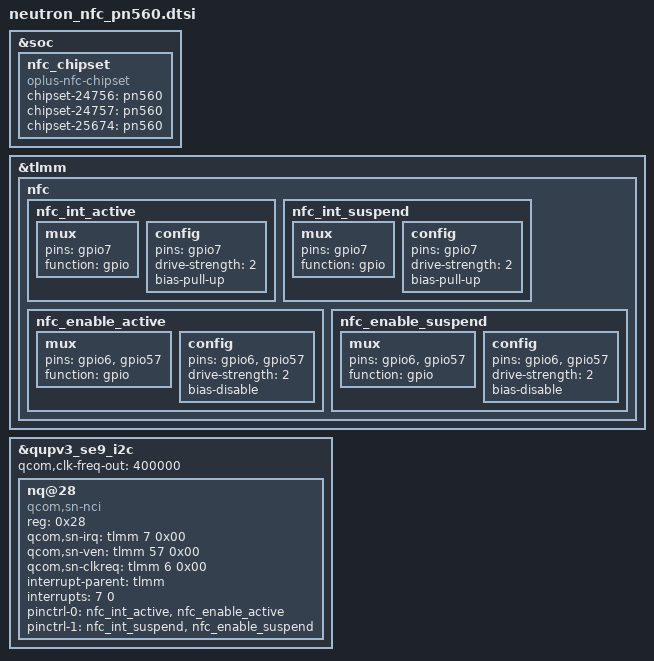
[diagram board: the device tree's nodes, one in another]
&soc {
    //add for nfc_chipset
    nfc_chipset {
        compatible = "oplus-nfc-chipset";
        chipset-24756 = "pn560";
        chipset-24757 = "pn560";
        chipset-25674 = "pn560";
    };
};


&tlmm {
	nfc {
		nfc_int_active: nfc_int_active {
			/* active state */
			mux {
				/* GPIO 7 NFC Read Interrupt */
				pins = "gpio7";
				function = "gpio";
			};

			config {
				pins = "gpio7";
				drive-strength = <2>; /* 2 MA */
				bias-pull-up;
			};
		};

		nfc_int_suspend: nfc_int_suspend {
			/* sleep state */
			mux {
				/* GPIO 7 NFC Read Interrupt */
				pins = "gpio7";
				function = "gpio";
			};

			config {
				pins = "gpio7";
				drive-strength = <2>; /* 2 MA */
				bias-pull-up;
			};
		};

		nfc_enable_active: nfc_enable_active {
            mux {
                /* Enable, Clock request gpios */
                pins = "gpio6", "gpio57";
                function = "gpio";
            };

            config {
                pins = "gpio6", "gpio57";
                drive-strength = <2>; /* 2 MA */
                bias-disable;
            };
        };

        nfc_enable_suspend: nfc_enable_suspend {
            mux {
                pins = "gpio6", "gpio57";
                function = "gpio";
            };

            config {
                pins = "gpio6", "gpio57";
                drive-strength = <2>; /* 2 MA */
                bias-disable;
			};
		};
	};
};

&qupv3_se9_i2c {
	status = "ok";
	qcom,clk-freq-out = <400000>;
	#address-cells = <1>;
	#size-cells = <0>;
	nq@28 {
		compatible = "qcom,sn-nci";
		reg = <0x28>;
 		qcom,sn-irq = <&tlmm 7 0x00>;
 		qcom,sn-ven = <&tlmm 57 0x00>;
 		qcom,sn-clkreq = <&tlmm 6 0x00>;
 		interrupt-parent = <&tlmm>;
 		interrupts = <7 0>;
 		interrupt-names = "nfc_irq";
 		pinctrl-names = "nfc_active", "nfc_suspend";
 		pinctrl-0 = <&nfc_int_active &nfc_enable_active>;
 		pinctrl-1 = <&nfc_int_suspend &nfc_enable_suspend>;
	};
};
